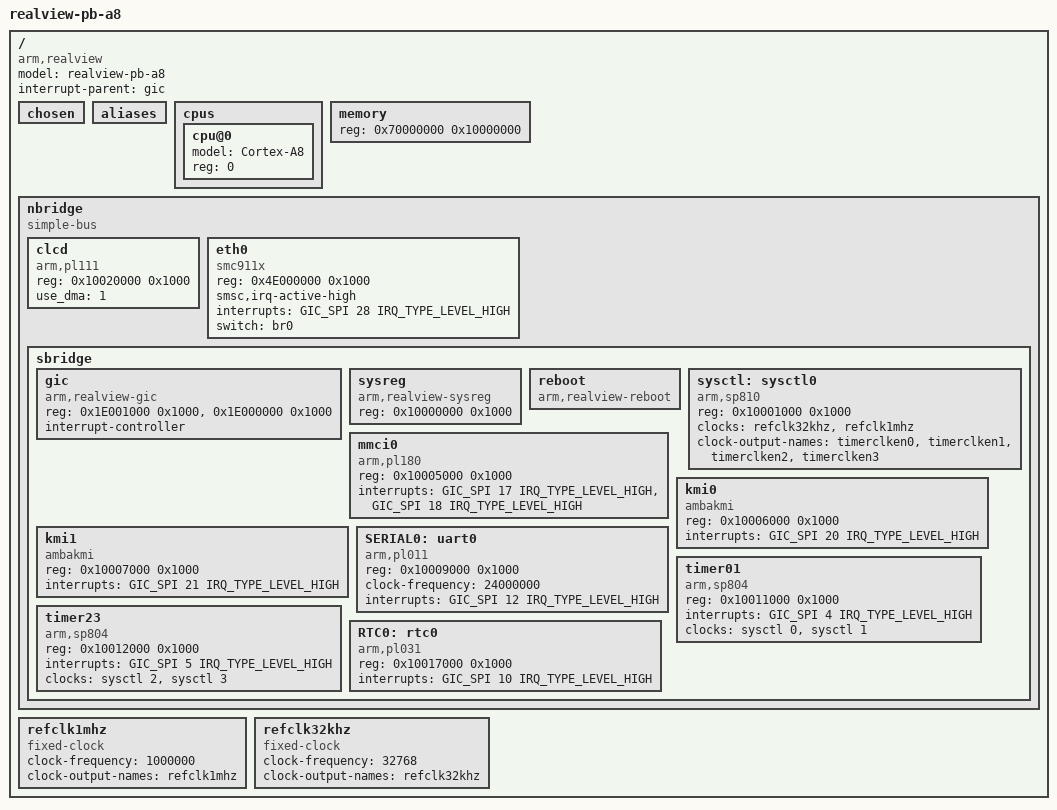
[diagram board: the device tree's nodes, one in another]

#include <dt-bindings/interrupt-controller/arm-gic.h>

/ {
	compatible = "arm,realview";
	model = "realview-pb-a8";
	interrupt-parent = <&gic>;
	#address-cells = <1>;
	#size-cells = <1>;

	chosen { };
	aliases { };

	cpus {
		#address-cells = <1>;
		#size-cells = <0>;

		cpu@0 {
			device_type = "cpu";
			model = "Cortex-A8";
			reg = <0>;
		};
	};

	memory {
		device_type = "memory"; 
		reg = <0x70000000 0x10000000>; /* 256 MB */
	};

	nbridge {
		#address-cells = <1>;
		#size-cells = <1>;
		compatible = "simple-bus";

		clcd {
	      		compatible = "arm,pl111";
	      		reg = <0x10020000 0x1000>;
			use_dma = <1>;
		};

		eth0 {
			compatible = "smc911x";
			reg = <0x4E000000 0x1000>;
			smsc,irq-active-high;
			interrupts = <GIC_SPI 28 IRQ_TYPE_LEVEL_HIGH>;
			switch = "br0";
		};

		sbridge {
			#address-cells = <1>;
			#size-cells = <1>;

			gic: gic { /* Generic Interrupt Controller */
		      		compatible = "arm,realview-gic";
				reg = <0x1E001000 0x1000>,
				      <0x1E000000 0x1000>;
				#interrupt-cells = <3>;
				interrupt-controller;
			};

			sysreg { /* System Registers */
		      		compatible = "arm,realview-sysreg";
		      		reg = <0x10000000 0x1000>;
			};

			reboot {
		      		compatible = "arm,realview-reboot";
			};

			sysctl: sysctl0 { /* System Controller */
		      		compatible = "arm,sp810";
		      		reg = <0x10001000 0x1000>;
				clocks = <&refclk32khz>, <&refclk1mhz>;
				clock-names = "refclk", "timclk", "apb_pclk";
				#clock-cells = <1>;
				clock-output-names = "timerclken0", "timerclken1", "timerclken2", "timerclken3";
			};

			mmci0 { /* Multimedia Card Interface */
		      		compatible = "arm,pl180";
		      		reg = <0x10005000 0x1000>;
				interrupts = <GIC_SPI 17 IRQ_TYPE_LEVEL_HIGH>,
					     <GIC_SPI 18 IRQ_TYPE_LEVEL_HIGH>;
			};

			kmi0 { /* Keyboard */
		      		compatible = "ambakmi";
		      		reg = <0x10006000 0x1000>;
				interrupts = <GIC_SPI 20 IRQ_TYPE_LEVEL_HIGH>;
			};

			kmi1 { /* Mouse */
		      		compatible = "ambakmi";
		      		reg = <0x10007000 0x1000>;
				interrupts = <GIC_SPI 21 IRQ_TYPE_LEVEL_HIGH>;
			};

			SERIAL0: uart0 {
		      		compatible = "arm,pl011";
		      		reg = <0x10009000 0x1000>;
				clock-frequency = <24000000>;
				interrupts = <GIC_SPI 12 IRQ_TYPE_LEVEL_HIGH>;
			};

			timer01 {
		      		compatible = "arm,sp804";
		      		reg = <0x10011000 0x1000>;
				interrupts = <GIC_SPI 4 IRQ_TYPE_LEVEL_HIGH>;
				clocks = <&sysctl 0>, <&sysctl 1>;
				clock-names = "timclken1", "timclken2";
			};

			timer23 {
		      		compatible = "arm,sp804";
		      		reg = <0x10012000 0x1000>;
				interrupts = <GIC_SPI 5 IRQ_TYPE_LEVEL_HIGH>;
				clocks = <&sysctl 2>, <&sysctl 3>;
				clock-names = "timclken1", "timclken2";
			};

			RTC0: rtc0 {
		      		compatible = "arm,pl031";
		      		reg = <0x10017000 0x1000>;
				interrupts = <GIC_SPI 10 IRQ_TYPE_LEVEL_HIGH>;
			};
		};
	};

	refclk1mhz: refclk1mhz {
		compatible = "fixed-clock";
		#clock-cells = <0>;
		clock-frequency = <1000000>;
		clock-output-names = "refclk1mhz";
	};

	refclk32khz: refclk32khz {
		compatible = "fixed-clock";
		#clock-cells = <0>;
		clock-frequency = <32768>;
		clock-output-names = "refclk32khz";
	};
};

